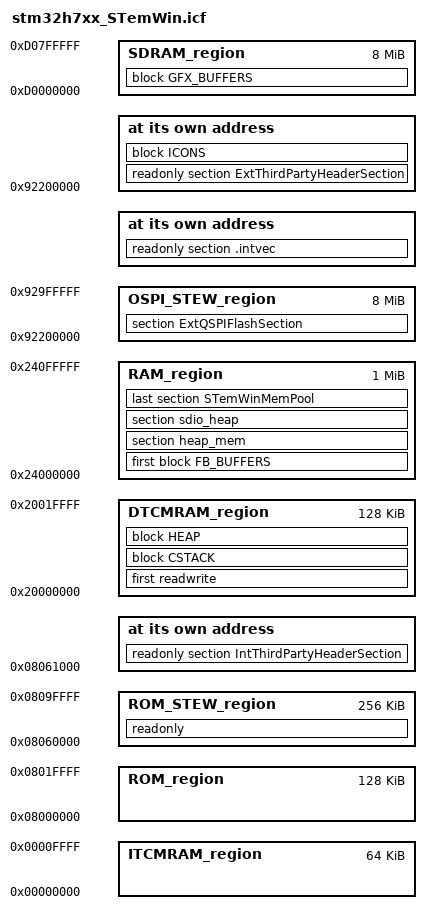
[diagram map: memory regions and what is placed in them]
/*###ICF### Section handled by ICF editor, don't touch! ****/
/*-Editor annotation file-*/
/* IcfEditorFile="$TOOLKIT_DIR$\config\ide\IcfEditor\cortex_v1_0.xml" */
/*-Specials-*/
define symbol __ICFEDIT_intvec_start__ = __C_START_ADDR;     /* 0x08060000 */
/*-Memory Regions-*/
define symbol __ICFEDIT_region_ROM_start__      = 0x08000000;
define symbol __ICFEDIT_region_ROM_end__        = 0x0801FFFF;     /*  128 Kbytes for the Menu Launcher */
define symbol __ICFEDIT_region_ROM_STEW_start__ = 0x08060000;
define symbol __ICFEDIT_region_ROM_STEW_end__   = 0x0809FFFF;     /*  256 Kbytes for STemWin demo */

/*-Internal RAM Memory Regions-*/
define symbol __ICFEDIT_region_ITCMRAM_start__ = 0x00000000;
define symbol __ICFEDIT_region_ITCMRAM_end__   = 0x0000FFFF;      /*   64 Kbytes */
define symbol __ICFEDIT_region_DTCMRAM_start__ = 0x20000000;
define symbol __ICFEDIT_region_DTCMRAM_end__   = 0x2001FFFF;      /*  128 Kbytes */
define symbol __ICFEDIT_region_RAM_start__     = 0x24000000;
define symbol __ICFEDIT_region_RAM_end__       = 0x240FFFFF;      /* 1024 Kbytes */

/*-External RAM Memory Regions-*/
define symbol __ICFEDIT_region_SDRAM_start__ = 0xD0000000;        /*    8 Mbytes */
define symbol __ICFEDIT_region_SDRAM_end__   = 0xD07FFFFF;

/*-Quad-SPI Memory Regions-*/
define symbol __ICFEDIT_region_OSPI_STEW_start__ = 0x92200000;
define symbol __ICFEDIT_region_OSPI_STEW_end__   = 0x929FFFFF;    /*    8 Mbytes for STemWin demo */

/*-Sizes-*/
define symbol __ICFEDIT_size_cstack__ = 0x1000;      /* 4 Kb */
define symbol __ICFEDIT_size_heap__   = 0x800;       /* 2 Kb */
/**** End of ICF editor section. ###ICF###*/

define memory mem with size = 4G;
define region ROM_region        = mem:[from __ICFEDIT_region_ROM_start__        to __ICFEDIT_region_ROM_end__];
define region ROM_STEW_region   = mem:[from __ICFEDIT_region_ROM_STEW_start__   to __ICFEDIT_region_ROM_STEW_end__];

define region ITCMRAM_region    = mem:[from __ICFEDIT_region_ITCMRAM_start__    to __ICFEDIT_region_ITCMRAM_end__];
define region DTCMRAM_region    = mem:[from __ICFEDIT_region_DTCMRAM_start__    to __ICFEDIT_region_DTCMRAM_end__];
define region RAM_region        = mem:[from __ICFEDIT_region_RAM_start__        to __ICFEDIT_region_RAM_end__];
define region SDRAM_region      = mem:[from __ICFEDIT_region_SDRAM_start__      to __ICFEDIT_region_SDRAM_end__];

define region OSPI_STEW_region  = mem:[from __ICFEDIT_region_OSPI_STEW_start__  to __ICFEDIT_region_OSPI_STEW_end__];

define block CSTACK     with alignment =  8, size = __ICFEDIT_size_cstack__    { };
define block HEAP       with alignment =  8, size = __ICFEDIT_size_heap__      { };
define block ICONS      with alignment = 32 { section demo_icon_section, section demo_logo_section };
define block GFX_BUFFERS  with alignment = 256  { first section gfx_buffers }; /* 12 Mbytes */
define block FB_BUFFERS with alignment = 32, fixed order { section framebuffer, section dma2d_palette };
/*-Third Party Demonstration Headers-*/
define symbol __thp_int_header_start__ = __ICFEDIT_region_ROM_STEW_start__ + 0x1000;
define symbol __thp_ext_header_start__ = __ICFEDIT_region_OSPI_STEW_start__;

initialize by copy { readwrite };
initialize manually { readonly data section DemoLoaderSection };
do not initialize  { section .noinit };
do not initialize  { section gfx_buffers };

place at address mem:__ICFEDIT_intvec_start__ { readonly section .intvec };

/*-Third Party headers Memory Placement-*/
place at address mem:__thp_int_header_start__   { readonly section IntThirdPartyHeaderSection };
place at address mem:__thp_ext_header_start__   { readonly section ExtThirdPartyHeaderSection, block ICONS };

place in ITCMRAM_region     { };
place in DTCMRAM_region     { first readwrite, block CSTACK, block HEAP };
place in RAM_region         { first block FB_BUFFERS
                            , section heap_mem, section sdio_heap
                            , last section STemWinMemPool };

place in SDRAM_region       { block GFX_BUFFERS };

place in ROM_STEW_region    { readonly };

place in OSPI_STEW_region   { section ExtQSPIFlashSection };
